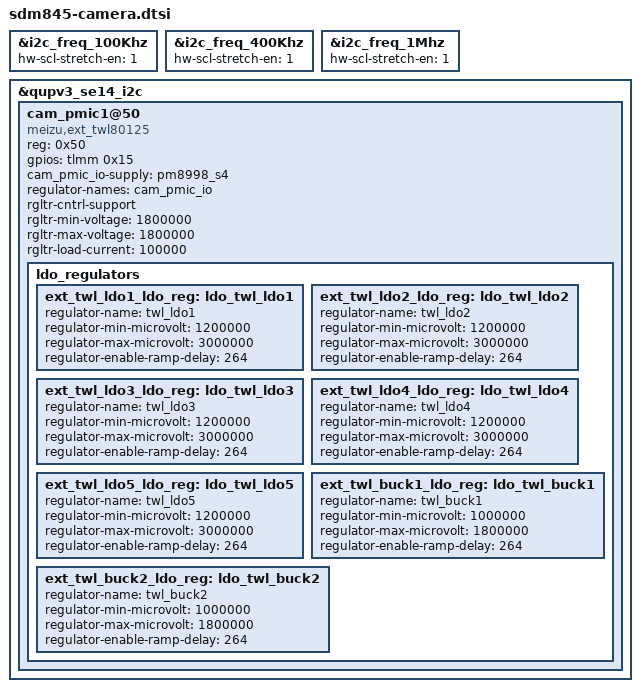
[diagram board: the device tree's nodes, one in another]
/*
 * Copyright (C) 2023 transaero21 <transaero21@elseboot.ru>
 *
 * SPDX-License-Identifier: GPL-2.0
 */

&i2c_freq_100Khz {
	hw-scl-stretch-en = <1>;
};

&i2c_freq_400Khz {
	hw-scl-stretch-en = <1>;
};

&i2c_freq_1Mhz {
	hw-scl-stretch-en = <1>;
};

&qupv3_se14_i2c {
	status = "ok";

	cam_pmic1@50 {
		compatible = "meizu,ext_twl80125";
		reg = <0x50>;
		gpios = <&tlmm 0x15 0x00>;
		cam_pmic_io-supply = <&pm8998_s4>;
		regulator-names = "cam_pmic_io";
		rgltr-cntrl-support;
		rgltr-min-voltage = <1800000>;
		rgltr-max-voltage = <1800000>;
		rgltr-load-current = <100000>;

		ldo_regulators {
			ext_twl_ldo1_ldo_reg: ldo_twl_ldo1 {
				regulator-name = "twl_ldo1";
				regulator-min-microvolt = <1200000>;
				regulator-max-microvolt = <3000000>;
				regulator-enable-ramp-delay = <264>;
			};

			ext_twl_ldo2_ldo_reg: ldo_twl_ldo2 {
				regulator-name = "twl_ldo2";
				regulator-min-microvolt = <1200000>;
				regulator-max-microvolt = <3000000>;
				regulator-enable-ramp-delay = <264>;
			};

			ext_twl_ldo3_ldo_reg: ldo_twl_ldo3 {
				regulator-name = "twl_ldo3";
				regulator-min-microvolt = <1200000>;
				regulator-max-microvolt = <3000000>;
				regulator-enable-ramp-delay = <264>;
			};

			ext_twl_ldo4_ldo_reg: ldo_twl_ldo4 {
				regulator-name = "twl_ldo4";
				regulator-min-microvolt = <1200000>;
				regulator-max-microvolt = <3000000>;
				regulator-enable-ramp-delay = <264>;
			};

			ext_twl_ldo5_ldo_reg: ldo_twl_ldo5 {
				regulator-name = "twl_ldo5";
				regulator-min-microvolt = <1200000>;
				regulator-max-microvolt = <3000000>;
				regulator-enable-ramp-delay = <264>;
			};

			ext_twl_buck1_ldo_reg: ldo_twl_buck1 {
				regulator-name = "twl_buck1";
				regulator-min-microvolt = <1000000>;
				regulator-max-microvolt = <1800000>;
				regulator-enable-ramp-delay = <264>;
			};

			ext_twl_buck2_ldo_reg: ldo_twl_buck2 {
				regulator-name = "twl_buck2";
				regulator-min-microvolt = <1000000>;
				regulator-max-microvolt = <1800000>;
				regulator-enable-ramp-delay = <264>;
			};
		};
	};
};
